# F28x7x_epwm_xbar_regs register map
Vendor: Texas Instruments
Peripheral module from a debugger description file (folder C2000).
Address unit: 16 bits
Registers are 32-bit, read-write, no defined reset value unless marked. A register's access mark holds for its fields unless they carry their own. Offsets are as the file gives them; lines under a group give offsets from that group; [hi:lo] are bit positions; {n}, {i} and the like mark numbered series; 'fields as' and 'values as' point back to an identical list; <NAME> marks a mode.

## EPWM_XBAR_REGS — EPWM XBAR Registers
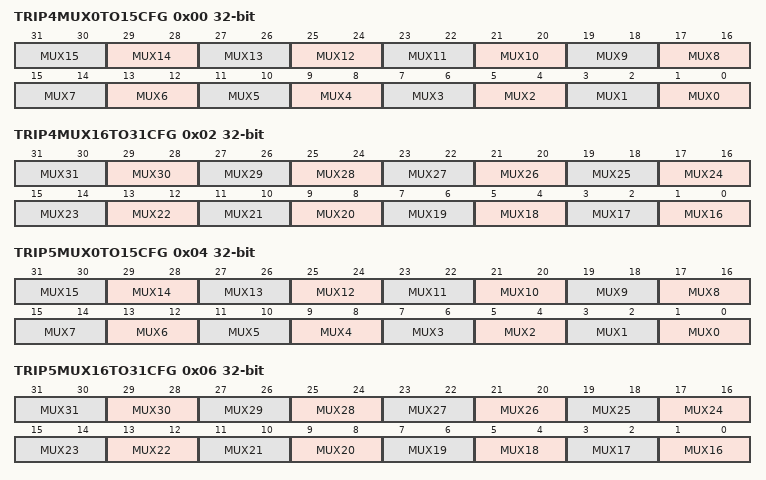
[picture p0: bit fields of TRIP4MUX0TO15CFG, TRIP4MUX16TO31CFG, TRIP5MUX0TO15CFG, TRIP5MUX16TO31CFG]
0x00 TRIP4MUX0TO15CFG — ePWM XBAR Mux Configuration for TRIP4
  [2n+1:2n] MUX{n} (n=0..15) — Mux{n} Configuration for TRIP4 of EPWM-XBAR
0x02 TRIP4MUX16TO31CFG — ePWM XBAR Mux Configuration for TRIP4
  [2n-31:2n-32] MUX{n} (n=16..31) — Mux{n} Configuration for TRIP4 of EPWM-XBAR
0x04 TRIP5MUX0TO15CFG — ePWM XBAR Mux Configuration for TRIP5
  [2n+1:2n] MUX{n} (n=0..15) — Mux{n} Configuration for TRIP5 of EPWM-XBAR
0x06 TRIP5MUX16TO31CFG — ePWM XBAR Mux Configuration for TRIP5
  [2n-31:2n-32] MUX{n} (n=16..31) — Mux{n} Configuration for TRIP5 of EPWM-XBAR
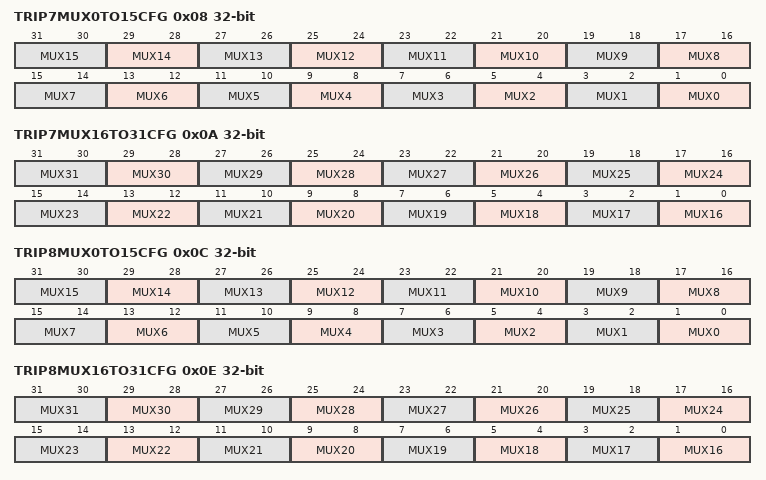
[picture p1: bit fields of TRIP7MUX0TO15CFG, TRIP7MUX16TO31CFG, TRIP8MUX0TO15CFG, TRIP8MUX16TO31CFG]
0x08 TRIP7MUX0TO15CFG — ePWM XBAR Mux Configuration for TRIP7
  [2n+1:2n] MUX{n} (n=0..15) — Mux{n} Configuration for TRIP7 of EPWM-XBAR
0x0A TRIP7MUX16TO31CFG — ePWM XBAR Mux Configuration for TRIP7
  [2n-31:2n-32] MUX{n} (n=16..31) — Mux{n} Configuration for TRIP7 of EPWM-XBAR
0x0C TRIP8MUX0TO15CFG — ePWM XBAR Mux Configuration for TRIP8
  [2n+1:2n] MUX{n} (n=0..15) — Mux{n} Configuration for TRIP8 of EPWM-XBAR
0x0E TRIP8MUX16TO31CFG — ePWM XBAR Mux Configuration for TRIP8
  [2n-31:2n-32] MUX{n} (n=16..31) — Mux{n} Configuration for TRIP8 of EPWM-XBAR
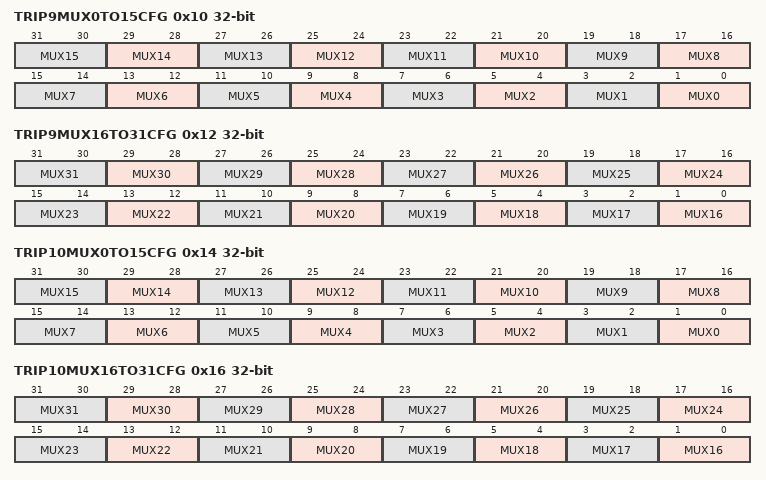
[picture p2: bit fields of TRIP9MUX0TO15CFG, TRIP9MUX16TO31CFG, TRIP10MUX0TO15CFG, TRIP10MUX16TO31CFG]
0x10 TRIP9MUX0TO15CFG — ePWM XBAR Mux Configuration for TRIP9
  [2n+1:2n] MUX{n} (n=0..15) — Mux{n} Configuration for TRIP9 of EPWM-XBAR
0x12 TRIP9MUX16TO31CFG — ePWM XBAR Mux Configuration for TRIP9
  [2n-31:2n-32] MUX{n} (n=16..31) — Mux{n} Configuration for TRIP9 of EPWM-XBAR
0x14 TRIP10MUX0TO15CFG — ePWM XBAR Mux Configuration for TRIP10
  [2n+1:2n] MUX{n} (n=0..15) — Mux{n} Configuration for TRIP10 of EPWM-XBAR
0x16 TRIP10MUX16TO31CFG — ePWM XBAR Mux Configuration for TRIP10
  [2n-31:2n-32] MUX{n} (n=16..31) — Mux{n} Configuration for TRIP10 of EPWM-XBAR
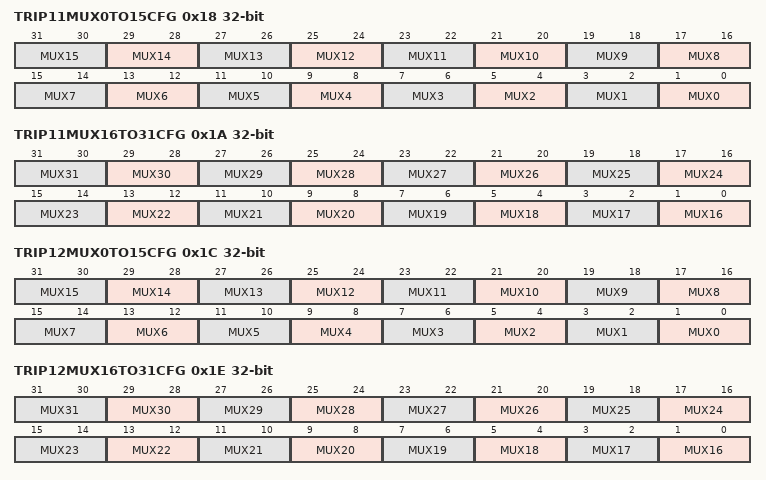
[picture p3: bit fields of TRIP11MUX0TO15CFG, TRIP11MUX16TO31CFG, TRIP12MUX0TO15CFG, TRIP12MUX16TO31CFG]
0x18 TRIP11MUX0TO15CFG — ePWM XBAR Mux Configuration for TRIP11
  [2n+1:2n] MUX{n} (n=0..15) — Mux{n} Configuration for TRIP11 of EPWM-XBAR
0x1A TRIP11MUX16TO31CFG — ePWM XBAR Mux Configuration for TRIP11
  [2n-31:2n-32] MUX{n} (n=16..31) — Mux{n} Configuration for TRIP11 of EPWM-XBAR
0x1C TRIP12MUX0TO15CFG — ePWM XBAR Mux Configuration for TRIP12
  [2n+1:2n] MUX{n} (n=0..15) — Mux{n} Configuration for TRIP12 of EPWM-XBAR
0x1E TRIP12MUX16TO31CFG — ePWM XBAR Mux Configuration for TRIP12
  [2n-31:2n-32] MUX{n} (n=16..31) — Mux{n} Configuration for TRIP12 of EPWM-XBAR
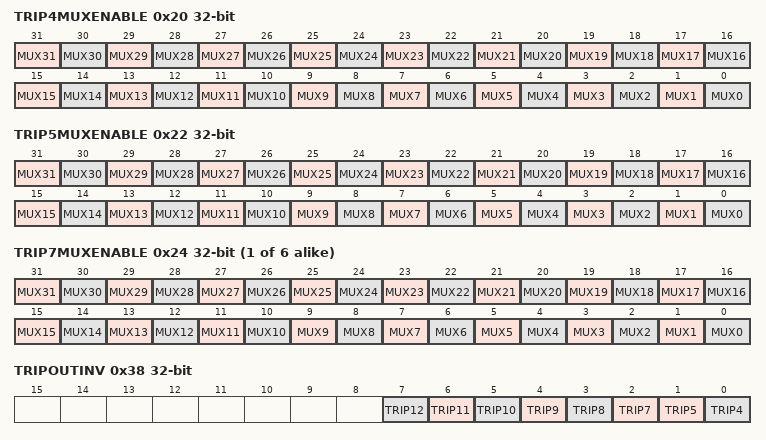
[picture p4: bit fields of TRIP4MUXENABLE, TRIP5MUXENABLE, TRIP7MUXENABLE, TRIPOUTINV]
0x20 TRIP4MUXENABLE — ePWM XBAR Mux Enable for TRIP4
  [n] MUX{n} (n=1..31) — Mux{n} to drive TRIP4 of EPWM-XBAR
  [0] MUX0 — mux0 to drive TRIP4 of EPWM-XBAR
0x22 TRIP5MUXENABLE — ePWM XBAR Mux Enable for TRIP5
  [n] MUX{n} (n=1..31) — Mux{n} to drive TRIP5 of EPWM-XBAR
  [0] MUX0 — mux0 to drive TRIP5 of EPWM-XBAR
{0x16+2i} TRIP{i}MUXENABLE (i=7..12) — ePWM XBAR Mux Enable for TRIP{i}
  [n] MUX{n} (n=1..31) — Mux{n} to drive TRIP{i} of EPWM-XBAR
  [0] MUX0 — mux0 to drive TRIP{i} of EPWM-XBAR
0x38 TRIPOUTINV — ePWM XBAR Output Inversion Register
  [n-5] TRIP{n} (n=7..12) — Selects polarity for TRIP{n} of EPWM-XBAR
  [1] TRIP5 — Selects polarity for TRIP5 of EPWM-XBAR
  [0] TRIP4 — Selects polarity for TRIP4 of EPWM-XBAR
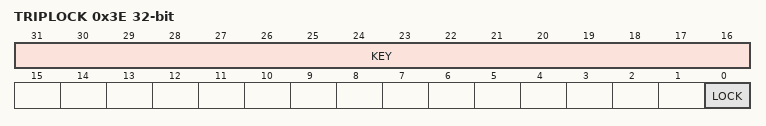
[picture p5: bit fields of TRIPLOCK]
0x3E TRIPLOCK access not given — ePWM XBAR Configuration Lock register
  [31:16] KEY — Write protection KEY (access R=0/W=1)
  [0] LOCK — Locks the configuration for EPWM-XBAR (access R/SOnce)
